# npcx4m8f register map
Registers are 8-bit, read-write, no defined reset value unless marked. A register's access mark holds for its fields unless they carry their own. Offsets are from the block's base; [hi:lo] are bit positions; {n}, {i} and the like mark numbered series.

## GDMA0-0 — General DMA Modulator 1
Base 0x40011000
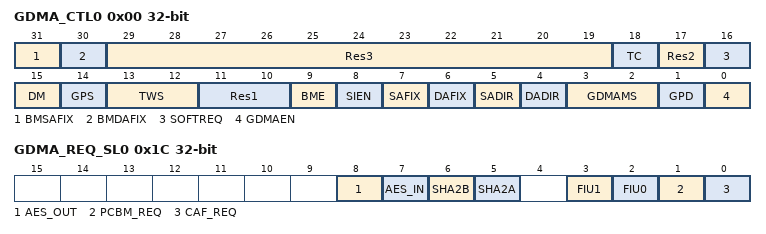
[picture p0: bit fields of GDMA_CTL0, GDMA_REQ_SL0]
0x00 GDMA_CTL0 32-bit
  [31] BMSAFIX, [30] BMDAFIX, [29:19] Res3, [18] TC, [17] Res2, [16] SOFTREQ, [15] DM, [14] GPS, [13:12] TWS, [11:10] Res1, [9] BME, [8] SIEN, [7] SAFIX, [6] DAFIX, [5] SADIR, [4] DADIR, [3:2] GDMAMS, [1] GPD, [0] GDMAEN
0x04 GDMA_SRCB0 32-bit
0x08 GDMA_DSTB0 32-bit
0x0C GDMA_TCNT0 32-bit
  [23:0] TFR_CNT
0x10 GDMA_CSRC0 32-bit
0x14 GDMA_CDST0 32-bit
0x18 GDMA_CTCNT0 32-bit
  [23:0] CURENT_TFR_CNT
0x1C GDMA_REQ_SL0 32-bit
  [8] AES_OUT, [7] AES_IN, [6] SHA2B, [5] SHA2A, [3] FIU1, [2] FIU0, [1] PCBM_REQ, [0] CAF_REQ

## GDMA0-1 — General DMA Modulator 2
Base 0x40011000
0x20 GDMA_CTL1 32-bit
  [31] BMSAFIX, [30] BMDAFIX, [29:19] Res3, [18] TC, [17] Res2, [16] SOFTREQ, [15] DM, [14] GPS, [13:12] TWS, [11:10] Res1, [9] BME, [8] SIEN, [7] SAFIX, [6] DAFIX, [6:5] SADIR, [4] DADIR, [3:2] GDMAMS, [1] GPD, [0] GDMAEN
0x24 GDMA_SRCB1 32-bit
0x28 GDMA_DSTB1 32-bit
0x2C GDMA_TCNT1 32-bit
  [23:0] TFR_CNT
0x30 GDMA_CSRC1 32-bit
0x34 GDMA_CDST1 32-bit
0x38 GDMA_CTCNT1 32-bit
  [23:0] CURENT_TFR_CNT
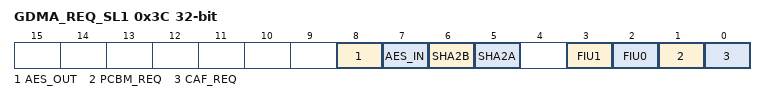
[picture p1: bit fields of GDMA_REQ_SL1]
0x3C GDMA_REQ_SL1 32-bit
  [8] AES_OUT, [7] AES_IN, [6] SHA2B, [5] SHA2A, [3] FIU1, [2] FIU0, [1] PCBM_REQ, [0] CAF_REQ

## MDMA1-0 — Mini DMA Modulator
Base 0x40011100
Same registers: MDMA2-0 0x40011200, MDMA3-0 0x40011300, MDMA4-0 0x40011400, MDMA5-0 0x40011500
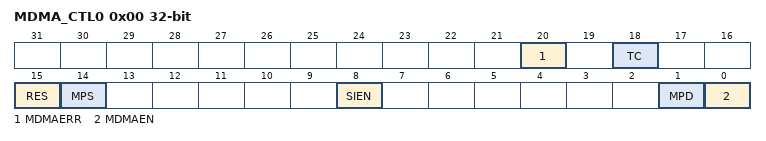
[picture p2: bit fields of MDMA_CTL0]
0x00 MDMA_CTL0 32-bit
  [20] MDMAERR, [18] TC, [15] RES, [14] MPS, [8] SIEN, [1] MPD, [0] MDMAEN
0x04 MDMA_SRCB0 32-bit
0x08 MDMA_DSTB0 32-bit
0x0C MDMA_TCNT0 32-bit
  [23:0] TFR_CNT
0x10 MDMA_CSRC0 32-bit
0x14 MDMA_CDST0 32-bit
0x18 MDMA_CTCNT0 32-bit
  [23:0] CURENT_TFR_CNT

## MDMA1-1 — Mini DMA Modulator
Base 0x40011100
Same registers: MDMA2-1 0x40011200, MDMA3-1 0x40011300, MDMA4-1 0x40011400, MDMA5-1 0x40011500
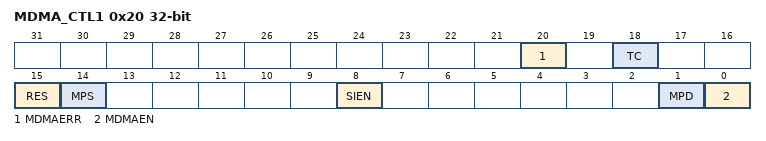
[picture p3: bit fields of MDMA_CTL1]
0x20 MDMA_CTL1 32-bit
  [20] MDMAERR, [18] TC, [15] RES, [14] MPS, [8] SIEN, [1] MPD, [0] MDMAEN
0x24 MDMA_SRCB1 32-bit
0x28 MDMA_DSTB1 32-bit
0x2C MDMA_TCNT1 32-bit
  [23:0] TFR_CNT
0x30 MDMA_CSRC1 32-bit
0x34 MDMA_CDST1 32-bit
0x38 MDMA_CTCNT1 32-bit
  [23:0] CURENT_TFR_CNT

## ADC — ADC Module
Base 0x400D1000
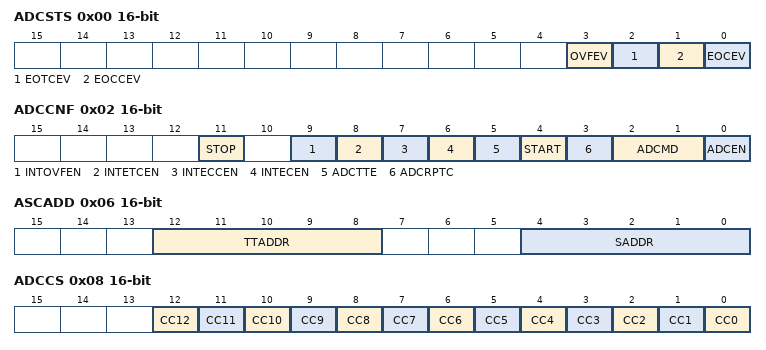
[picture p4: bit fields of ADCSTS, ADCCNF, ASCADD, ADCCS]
0x00 ADCSTS 16-bit
  [3] OVFEV, [2] EOTCEV, [1] EOCCEV, [0] EOCEV
0x02 ADCCNF 16-bit
  [11] STOP, [9] INTOVFEN, [8] INTETCEN, [7] INTECCEN, [6] INTECEN, [5] ADCTTE, [4] START, [3] ADCRPTC, [2:1] ADCMD, [0] ADCEN
0x04 ATCTL 16-bit
0x06 ASCADD 16-bit
  [12:8] TTADDR, [4:0] SADDR
0x08 ADCCS 16-bit
  [n] CC{n} (n=0..12)
{0x12+2i} THRCTL{i} 16-bit (i=1..3)
  [15] THEN, [14] L_H, [13:10] CHNSEL, [9:2] THRVAL8, [9:2] THRVAL, [9:0] THRVAL10, [9:0] THRVAL
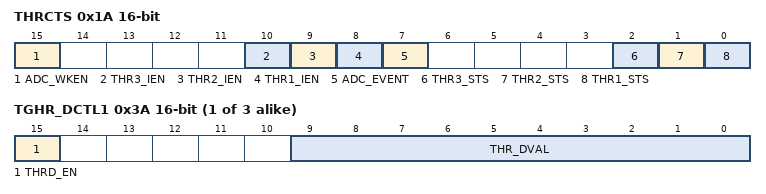
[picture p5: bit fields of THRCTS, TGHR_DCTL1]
0x1A THRCTS 16-bit
  [15] ADC_WKEN, [10] THR3_IEN, [9] THR2_IEN, [8] THR1_IEN, [7] ADC_EVENT, [2] THR3_STS, [1] THR2_STS, [0] THR1_STS
{0x38+2i} TGHR_DCTL{i} 16-bit (i=1..3)
  [15] THRD_EN, [9:0] THR_DVAL
{0x40+2i} CHN{i}DAT 16-bit (i=0..4)
  [15] NEW, [9:2] CHDAT8, [9:2] CHDAT, [9:0] CHDAT10, [9:0] CHDAT

## PWM-1 — Pluse-Width Modulator
Base 0x40080000
Same registers: PWM-2 0x40082000, PWM-3 0x40084000, PWM-4 0x40086000, PWM-5 0x40088000, PWM-6 0x4008A000, PWM-7 0x4008C000, PWM-8 0x4008E000
0x00 PRSCn
0x02 CTRn
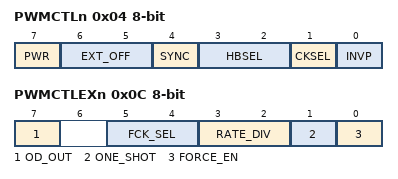
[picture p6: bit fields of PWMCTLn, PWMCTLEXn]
0x04 PWMCTLn
  [7] PWR, [6:5] EXT_OFF, [4] SYNC, [3:2] HBSEL, [1] CKSEL, [0] INVP
0x06 DCRn
0x08 SEQLn
0x0A SEQHn
0x0C PWMCTLEXn
  [7] OD_OUT, [5:4] FCK_SEL, [3:2] RATE_DIV, [1] ONE_SHOT, [0] FORCE_EN

## MIWU-1 — MULTI-INPUT WAKE-UP
Base 0x400BB000
Same registers: MIWU-1 0x400BD000, MIWU-1 0x400BD000, MIWU-1 0x400BD000, MIWU-1 0x400BD000, MIWU-1 0x400BF000, MIWU-1 0x400BF000
0x00 WKEDG1
0x01 WKAEDG1
0x02 WKMOD1
0x03 WKPND1
0x04 WKPCL1
0x05 WKEN1
0x06 WKST1
0x07 WKINEN1

## MIWU-2 — MULTI-INPUT WAKE-UP
Base 0x400BB000
Same registers: MIWU-2 0x400BD000, MIWU-2 0x400BD000, MIWU-2 0x400BD000, MIWU-2 0x400BD000, MIWU-2 0x400BF000, MIWU-2 0x400BF000
0x10 WKEDG1
0x11 WKAEDG1
0x12 WKMOD1
0x13 WKPND1
0x14 WKPCL1
0x15 WKEN1
0x16 WKST1
0x17 WKINEN1
